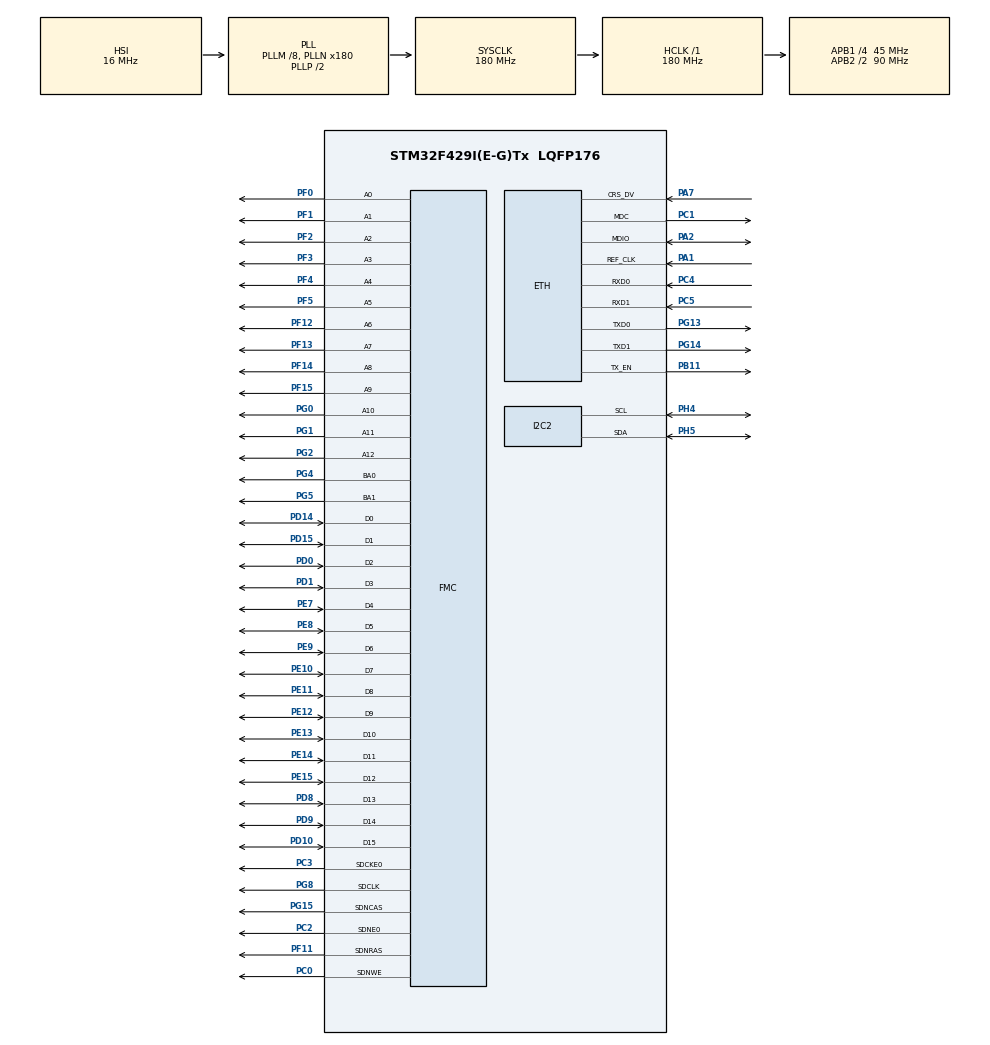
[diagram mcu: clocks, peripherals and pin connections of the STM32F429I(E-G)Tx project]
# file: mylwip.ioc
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ETH.MediaInterface=ETH_MEDIA_INTERFACE_RMII
ETH.PHY_DUPLEX_STATUS=0x0010
ETH.PHY_Name_RMII=userPHY
ETH.PHY_SPEED_STATUS=0x0004
ETH.PHY_SR=0x1F
ETH.PHY_User_Name=LAN8720
ETH.PhyAddress=0
ETH.RxMode=ETH_RXINTERRUPT_MODE
FMC.CASLatency1=FMC_SDRAM_CAS_LATENCY_3
FMC.ColumnBitsNumber1=FMC_SDRAM_COLUMN_BITS_NUM_9
FMC.ExitSelfRefreshDelay1=8
FMC.LoadToActiveDelay1=2
FMC.RCDDelay1=2
FMC.RPDelay1=2
FMC.RPDelay2=2
FMC.ReadBurst1=FMC_SDRAM_RBURST_ENABLE
FMC.ReadBurst2=FMC_SDRAM_RBURST_ENABLE
FMC.ReadPipeDelay1=FMC_SDRAM_RPIPE_DELAY_1
FMC.ReadPipeDelay2=FMC_SDRAM_RPIPE_DELAY_1
FMC.RowCycleDelay1=6
FMC.RowCycleDelay2=6
FMC.SDClockPeriod1=FMC_SDRAM_CLOCK_PERIOD_2
FMC.SDClockPeriod2=FMC_SDRAM_CLOCK_PERIOD_2
FMC.SelfRefreshTime1=6
FMC.WriteRecoveryTime1=4
FREERTOS.HEAP_NUMBER=5
FREERTOS.Tasks01=defaultTask,24,128,StartDefaultTask,Default,NULL,Dynamic,NULL,NULL
FREERTOS.configENABLE_FPU=1
LWIP.GATEWAY_ADDRESS=192.168.031.001
LWIP.IP_ADDRESS=192.168.031.222
LWIP.LWIP_DHCP=0
LWIP.NETMASK_ADDRESS=255.255.255.000
LWIP.TCP_QUEUE_OOSEQ=0
LWIP.Version=v2.1.2_Cube
Mcu.Family=STM32F4
Mcu.Name=STM32F429I(E-G)Tx
Mcu.Package=LQFP176
NVIC.ETH_IRQn=true\:5\:0\:false\:false\:true\:true\:false\:true
NVIC.PriorityGroup=NVIC_PRIORITYGROUP_4
NVIC.TIM8_UP_TIM13_IRQn=true\:15\:0\:false\:false\:true\:false\:false\:true
NVIC.TimeBase=TIM8_UP_TIM13_IRQn
NVIC.TimeBaseIP=TIM8
PA1.Mode=RMII
PA1.Signal=ETH_REF_CLK
PA2.Mode=RMII
PA2.Signal=ETH_MDIO
PA7.Mode=RMII
PA7.Signal=ETH_CRS_DV
PB11.Mode=RMII
PB11.Signal=ETH_TX_EN
PC0.Signal=FMC_SDNWE
PC1.Mode=RMII
PC1.Signal=ETH_MDC
PC2.Mode=SdramChipSelect1_1
PC2.Signal=FMC_SDNE0
PC3.Mode=SdramChipSelect1_1
PC3.Signal=FMC_SDCKE0
PC4.Mode=RMII
PC4.Signal=ETH_RXD0
PC5.Mode=RMII
PC5.Signal=ETH_RXD1
PD0.Signal=FMC_D2_DA2
PD1.Signal=FMC_D3_DA3
PD10.Signal=FMC_D15_DA15
PD14.Signal=FMC_D0_DA0
PD15.Signal=FMC_D1_DA1
PD8.Signal=FMC_D13_DA13
PD9.Signal=FMC_D14_DA14
PE10.Signal=FMC_D7_DA7
PE11.Signal=FMC_D8_DA8
PE12.Signal=FMC_D9_DA9
PE13.Signal=FMC_D10_DA10
PE14.Signal=FMC_D11_DA11
PE15.Signal=FMC_D12_DA12
PE7.Signal=FMC_D4_DA4
PE8.Signal=FMC_D5_DA5
PE9.Signal=FMC_D6_DA6
PF0.Signal=FMC_A0
PF1.Signal=FMC_A1
PF11.Signal=FMC_SDNRAS
PF12.Signal=FMC_A6
PF13.Signal=FMC_A7
PF14.Signal=FMC_A8
PF15.Signal=FMC_A9
PF2.Signal=FMC_A2
PF3.Signal=FMC_A3
PF4.Signal=FMC_A4
PF5.Signal=FMC_A5
PG0.Signal=FMC_A10
PG1.Signal=FMC_A11
PG13.Mode=RMII
PG13.Signal=ETH_TXD0
PG14.Mode=RMII
PG14.Signal=ETH_TXD1
PG15.Signal=FMC_SDNCAS
PG2.Signal=FMC_A12
PG4.Signal=FMC_A14_BA0
PG5.Signal=FMC_A15_BA1
PG8.Signal=FMC_SDCLK
PH4.Mode=I2C
PH4.Signal=I2C2_SCL
PH5.Mode=I2C
PH5.Signal=I2C2_SDA
ProjectManager.HeapSize=0x200
ProjectManager.StackSize=0x400
ProjectManager.TargetToolchain=MDK-ARM V5.32
RCC.48MHZClocksFreq_Value=90000000
RCC.AHBFreq_Value=180000000
RCC.APB1CLKDivider=RCC_HCLK_DIV4
RCC.APB1Freq_Value=45000000
RCC.APB1TimFreq_Value=90000000
RCC.APB2CLKDivider=RCC_HCLK_DIV2
RCC.APB2Freq_Value=90000000
RCC.APB2TimFreq_Value=180000000
RCC.CortexFreq_Value=180000000
RCC.HCLKFreq_Value=180000000
RCC.HSE_VALUE=25000000
RCC.HSI_VALUE=16000000
RCC.LSE_VALUE=32768
RCC.PLLM=8
RCC.PLLN=180
RCC.SYSCLKFreq_VALUE=180000000
RCC.SYSCLKSource=RCC_SYSCLKSOURCE_PLLCLK
RCC.VCOOutputFreq_Value=360000000
SH.FMC_A0.0=FMC_A0,13b-sda1
SH.FMC_A1.0=FMC_A1,13b-sda1
SH.FMC_A10.0=FMC_A10,13b-sda1
SH.FMC_A11.0=FMC_A11,13b-sda1
SH.FMC_A12.0=FMC_A12,13b-sda1
SH.FMC_A14_BA0.0=FMC_BA0,FourSdramBanks1
SH.FMC_A15_BA1.0=FMC_BA1,FourSdramBanks1
SH.FMC_A2.0=FMC_A2,13b-sda1
SH.FMC_A3.0=FMC_A3,13b-sda1
SH.FMC_A4.0=FMC_A4,13b-sda1
SH.FMC_A5.0=FMC_A5,13b-sda1
SH.FMC_A6.0=FMC_A6,13b-sda1
SH.FMC_A7.0=FMC_A7,13b-sda1
SH.FMC_A8.0=FMC_A8,13b-sda1
SH.FMC_A9.0=FMC_A9,13b-sda1
SH.FMC_D0_DA0.0=FMC_D0,sd-16b-d1
SH.FMC_D10_DA10.0=FMC_D10,sd-16b-d1
SH.FMC_D11_DA11.0=FMC_D11,sd-16b-d1
SH.FMC_D12_DA12.0=FMC_D12,sd-16b-d1
SH.FMC_D13_DA13.0=FMC_D13,sd-16b-d1
SH.FMC_D14_DA14.0=FMC_D14,sd-16b-d1
SH.FMC_D15_DA15.0=FMC_D15,sd-16b-d1
SH.FMC_D1_DA1.0=FMC_D1,sd-16b-d1
SH.FMC_D2_DA2.0=FMC_D2,sd-16b-d1
SH.FMC_D3_DA3.0=FMC_D3,sd-16b-d1
SH.FMC_D4_DA4.0=FMC_D4,sd-16b-d1
SH.FMC_D5_DA5.0=FMC_D5,sd-16b-d1
SH.FMC_D6_DA6.0=FMC_D6,sd-16b-d1
SH.FMC_D7_DA7.0=FMC_D7,sd-16b-d1
SH.FMC_D8_DA8.0=FMC_D8,sd-16b-d1
SH.FMC_D9_DA9.0=FMC_D9,sd-16b-d1
SH.FMC_SDCLK.0=FMC_SDCLK,13b-sda1
SH.FMC_SDNCAS.0=FMC_SDNCAS,13b-sda1
SH.FMC_SDNRAS.0=FMC_SDNRAS,13b-sda1
SH.FMC_SDNWE.0=FMC_SDNWE,13b-sda1
VP_FREERTOS_VS_CMSIS_V2.Mode=CMSIS_V2
VP_LWIP_VS_Enabled.Mode=Enabled
VP_SYS_VS_tim8.Mode=TIM8
board=custom

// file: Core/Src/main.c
/* USER CODE BEGIN Header */
/**
  ******************************************************************************
  * @file           : main.c
  * @brief          : Main program body
  ******************************************************************************
  * @attention
  *
  * Copyright (c) 2021 STMicroelectronics.
  * All rights reserved.
  *
  * This software is licensed under terms that can be found in the LICENSE file
  * in the root directory of this software component.
  * If no LICENSE file comes with this software, it is provided AS-IS.
  *
  ******************************************************************************
  */
/* USER CODE END Header */
#include "main.h"
#include "cmsis_os.h"
#include "lwip.h"

/* USER CODE BEGIN Includes */
#include "cmsis_os2.h"
#include <stdint.h>
/* USER CODE END Includes */

I2C_HandleTypeDef hi2c2;

SDRAM_HandleTypeDef hsdram1;

/* Definitions for defaultTask */
osThreadId_t defaultTaskHandle;
const osThreadAttr_t defaultTask_attributes = {
  .name = "defaultTask",
  .stack_size = 128 * 4,
  .priority = (osPriority_t) osPriorityNormal,
};

void SystemClock_Config(void);
static void MX_GPIO_Init(void);
static void MX_FMC_Init(void);
static void MX_I2C2_Init(void);
void StartDefaultTask(void *argument);

/* USER CODE BEGIN PFP */
void testmemory(void);
void mysdraminit(void);

/* USER CODE END PFP */

int main(void)
{

  /* MCU Configuration--------------------------------------------------------*/

  /* Reset of all peripherals, Initializes the Flash interface and the Systick. */
  HAL_Init();

  /* Configure the system clock */
  SystemClock_Config();

  /* Initialize all configured peripherals */
  MX_GPIO_Init();
  MX_FMC_Init();
  MX_I2C2_Init();
  /* USER CODE BEGIN 2 */
  mysdraminit();
  /* USER CODE END 2 */

  /* Init scheduler */
  osKernelInitialize();

  /* Create the thread(s) */
  /* creation of defaultTask */
  defaultTaskHandle = osThreadNew(StartDefaultTask, NULL, &defaultTask_attributes);

  /* Start scheduler */
  osKernelStart();

  /* We should never get here as control is now taken by the scheduler */
  /* Infinite loop */
  while (1)
  {

  }
}

void SystemClock_Config(void)
{
  RCC_OscInitTypeDef RCC_OscInitStruct = {0};
  RCC_ClkInitTypeDef RCC_ClkInitStruct = {0};

  /** Configure the main internal regulator output voltage
  */
  __HAL_RCC_PWR_CLK_ENABLE();
  __HAL_PWR_VOLTAGESCALING_CONFIG(PWR_REGULATOR_VOLTAGE_SCALE1);
  /** Initializes the RCC Oscillators according to the specified parameters
  * in the RCC_OscInitTypeDef structure.
  */
  RCC_OscInitStruct.OscillatorType = RCC_OSCILLATORTYPE_HSI;
  RCC_OscInitStruct.HSIState = RCC_HSI_ON;
  RCC_OscInitStruct.HSICalibrationValue = RCC_HSICALIBRATION_DEFAULT;
  RCC_OscInitStruct.PLL.PLLState = RCC_PLL_ON;
  RCC_OscInitStruct.PLL.PLLSource = RCC_PLLSOURCE_HSI;
  RCC_OscInitStruct.PLL.PLLM = 8;
  RCC_OscInitStruct.PLL.PLLN = 180;
  RCC_OscInitStruct.PLL.PLLP = RCC_PLLP_DIV2;
  RCC_OscInitStruct.PLL.PLLQ = 4;
  if (HAL_RCC_OscConfig(&RCC_OscInitStruct) != HAL_OK)
  {
    Error_Handler();
  }
  /** Activate the Over-Drive mode
  */
  if (HAL_PWREx_EnableOverDrive() != HAL_OK)
  {
    Error_Handler();
  }
  /** Initializes the CPU, AHB and APB buses clocks
  */
  RCC_ClkInitStruct.ClockType = RCC_CLOCKTYPE_HCLK|RCC_CLOCKTYPE_SYSCLK
                              |RCC_CLOCKTYPE_PCLK1|RCC_CLOCKTYPE_PCLK2;
  RCC_ClkInitStruct.SYSCLKSource = RCC_SYSCLKSOURCE_PLLCLK;
  RCC_ClkInitStruct.AHBCLKDivider = RCC_SYSCLK_DIV1;
  RCC_ClkInitStruct.APB1CLKDivider = RCC_HCLK_DIV4;
  RCC_ClkInitStruct.APB2CLKDivider = RCC_HCLK_DIV2;

  if (HAL_RCC_ClockConfig(&RCC_ClkInitStruct, FLASH_LATENCY_5) != HAL_OK)
  {
    Error_Handler();
  }
}

static void MX_I2C2_Init(void)
{

  hi2c2.Instance = I2C2;
  hi2c2.Init.ClockSpeed = 100000;
  hi2c2.Init.DutyCycle = I2C_DUTYCYCLE_2;
  hi2c2.Init.OwnAddress1 = 0;
  hi2c2.Init.AddressingMode = I2C_ADDRESSINGMODE_7BIT;
  hi2c2.Init.DualAddressMode = I2C_DUALADDRESS_DISABLE;
  hi2c2.Init.OwnAddress2 = 0;
  hi2c2.Init.GeneralCallMode = I2C_GENERALCALL_DISABLE;
  hi2c2.Init.NoStretchMode = I2C_NOSTRETCH_DISABLE;
  if (HAL_I2C_Init(&hi2c2) != HAL_OK)
  {
    Error_Handler();
  }
  /** Configure Analogue filter
  */
  if (HAL_I2CEx_ConfigAnalogFilter(&hi2c2, I2C_ANALOGFILTER_ENABLE) != HAL_OK)
  {
    Error_Handler();
  }
  /** Configure Digital filter
  */
  if (HAL_I2CEx_ConfigDigitalFilter(&hi2c2, 0) != HAL_OK)
  {
    Error_Handler();
  }

}

/* FMC initialization function */
static void MX_FMC_Init(void)
{

  FMC_SDRAM_TimingTypeDef SdramTiming = {0};

  /** Perform the SDRAM1 memory initialization sequence
  */
  hsdram1.Instance = FMC_SDRAM_DEVICE;
  /* hsdram1.Init */
  hsdram1.Init.SDBank = FMC_SDRAM_BANK1;
  hsdram1.Init.ColumnBitsNumber = FMC_SDRAM_COLUMN_BITS_NUM_9;
  hsdram1.Init.RowBitsNumber = FMC_SDRAM_ROW_BITS_NUM_13;
  hsdram1.Init.MemoryDataWidth = FMC_SDRAM_MEM_BUS_WIDTH_16;
  hsdram1.Init.InternalBankNumber = FMC_SDRAM_INTERN_BANKS_NUM_4;
  hsdram1.Init.CASLatency = FMC_SDRAM_CAS_LATENCY_3;
  hsdram1.Init.WriteProtection = FMC_SDRAM_WRITE_PROTECTION_DISABLE;
  hsdram1.Init.SDClockPeriod = FMC_SDRAM_CLOCK_PERIOD_2;
  hsdram1.Init.ReadBurst = FMC_SDRAM_RBURST_ENABLE;
  hsdram1.Init.ReadPipeDelay = FMC_SDRAM_RPIPE_DELAY_1;
  /* SdramTiming */
  SdramTiming.LoadToActiveDelay = 2;
  SdramTiming.ExitSelfRefreshDelay = 8;
  SdramTiming.SelfRefreshTime = 6;
  SdramTiming.RowCycleDelay = 6;
  SdramTiming.WriteRecoveryTime = 4;
  SdramTiming.RPDelay = 2;
  SdramTiming.RCDDelay = 2;

  if (HAL_SDRAM_Init(&hsdram1, &SdramTiming) != HAL_OK)
  {
    Error_Handler( );
  }

}

static void MX_GPIO_Init(void)
{

  /* GPIO Ports Clock Enable */
  __HAL_RCC_GPIOF_CLK_ENABLE();
  __HAL_RCC_GPIOC_CLK_ENABLE();
  __HAL_RCC_GPIOA_CLK_ENABLE();
  __HAL_RCC_GPIOH_CLK_ENABLE();
  __HAL_RCC_GPIOG_CLK_ENABLE();
  __HAL_RCC_GPIOE_CLK_ENABLE();
  __HAL_RCC_GPIOB_CLK_ENABLE();
  __HAL_RCC_GPIOD_CLK_ENABLE();

}

void StartDefaultTask(void *argument)
{
  /* init code for LWIP */
  MX_LWIP_Init();
  /* USER CODE BEGIN 5 */
  //testmemory();
  /* Infinite loop */
  for(;;)
  {
    osDelay(1);
  }
  /* USER CODE END 5 */
}

void HAL_TIM_PeriodElapsedCallback(TIM_HandleTypeDef *htim)
{
  if (htim->Instance == TIM8) {
    HAL_IncTick();
  }
}

void Error_Handler(void)
{
  __disable_irq();
  while (1)
  {
  }
}
